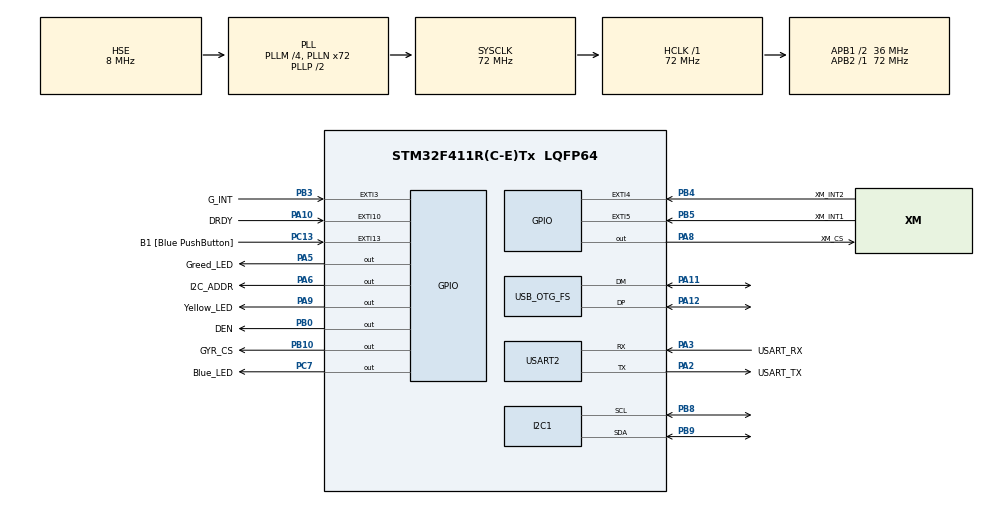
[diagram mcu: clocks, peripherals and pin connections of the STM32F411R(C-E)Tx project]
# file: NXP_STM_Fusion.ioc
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FREERTOS.INCLUDE_vTaskDelayUntil=1
FREERTOS.Tasks01=defaultTask,0,1024,StartDefaultTask
FREERTOS.configCHECK_FOR_STACK_OVERFLOW=1
FREERTOS.configUSE_MALLOC_FAILED_HOOK=1
FREERTOS.configUSE_TICK_HOOK=1
I2C1.I2C_Mode=I2C_Fast
Mcu.Family=STM32F4
Mcu.Name=STM32F411R(C-E)Tx
Mcu.Package=LQFP64
NVIC.EXTI15_10_IRQn=true\:5\:0\:false
NVIC.EXTI3_IRQn=true\:5\:0\:false
NVIC.EXTI4_IRQn=true\:5\:0\:false
NVIC.EXTI9_5_IRQn=true\:5\:0\:false
NVIC.OTG_FS_IRQn=true\:5\:0\:false
NVIC.PriorityGroup=NVIC_PRIORITYGROUP_4
NVIC.TIM1_UP_TIM10_IRQn=true\:5\:0\:false
NVIC.USART2_IRQn=true\:5\:0\:false
PA10.GPIO_Label=DRDY
PA10.Signal=GPXTI10
PA11.Mode=Device_Only
PA11.Signal=USB_OTG_FS_DM
PA12.Mode=Device_Only
PA12.Signal=USB_OTG_FS_DP
PA13.GPIO_Label=TMS
PA13.Mode=Serial-Wire
PA13.Signal=SYS_JTMS-SWDIO
PA14.GPIO_Label=TCK
PA14.Mode=Serial-Wire
PA14.Signal=SYS_JTCK-SWCLK
PA2.GPIO_Label=USART_TX
PA2.Mode=Asynchronous
PA2.Signal=USART2_TX
PA3.GPIO_Label=USART_RX
PA3.Mode=Asynchronous
PA3.Signal=USART2_RX
PA5.GPIO_Label=Greed_LED
PA5.Signal=GPIO_Output
PA6.GPIO_Label=I2C_ADDR
PA6.Signal=GPIO_Output
PA8.GPIO_Label=XM_CS
PA8.Signal=GPIO_Output
PA9.GPIO_Label=Yellow_LED
PA9.Signal=GPIO_Output
PB0.GPIO_Label=DEN
PB0.Signal=GPIO_Output
PB10.GPIO_Label=GYR_CS
PB10.Signal=GPIO_Output
PB3.GPIO_Label=G_INT
PB3.Signal=GPXTI3
PB4.GPIO_Label=XM_INT2
PB4.Signal=GPXTI4
PB5.GPIO_Label=XM_INT1
PB5.Signal=GPXTI5
PB8.Mode=I2C
PB8.Signal=I2C1_SCL
PB9.Mode=I2C
PB9.Signal=I2C1_SDA
PC13-ANTI_TAMP.GPIO_Label=B1 [Blue PushButton]
PC13-ANTI_TAMP.GPIO_ModeDefaultEXTI=GPIO_MODE_IT_RISING
PC13-ANTI_TAMP.Signal=GPXTI13
PC14-OSC32_IN.Mode=LSE-External-Oscillator
PC14-OSC32_IN.Signal=RCC_OSC32_IN
PC15-OSC32_OUT.Mode=LSE-External-Oscillator
PC15-OSC32_OUT.Signal=RCC_OSC32_OUT
PC7.GPIO_Label=Blue_LED
PC7.Signal=GPIO_Output
PH0\ -\ OSC_IN.Mode=HSE-External-Clock-Source
PH0\ -\ OSC_IN.Signal=RCC_OSC_IN
PH1\ -\ OSC_OUT.Mode=HSE-External-Clock-Source
PH1\ -\ OSC_OUT.Signal=RCC_OSC_OUT
ProjectManager.TargetToolchain=MDK-ARM V5
RCC.48MHZClocksFreq_Value=48000000
RCC.AHBFreq_Value=72000000
RCC.APB1CLKDivider=RCC_HCLK_DIV2
RCC.APB1Freq_Value=36000000
RCC.APB1TimFreq_Value=72000000
RCC.APB2Freq_Value=72000000
RCC.APB2TimFreq_Value=72000000
RCC.CortexFreq_Value=72000000
RCC.FLatency-AdvancedSettings=FLASH_LATENCY_2
RCC.HCLKFreq_Value=72000000
RCC.HSE_VALUE=8000000
RCC.HSI_VALUE=16000000
RCC.PLLM=4
RCC.PLLN=72
RCC.PLLQ=3
RCC.SYSCLKFreq_VALUE=72000000
RCC.SYSCLKSource=RCC_SYSCLKSOURCE_PLLCLK
RCC.VCOOutputFreq_Value=144000000
USB_DEVICE.PID_CDC_FS=0x5740
USB_DEVICE.USBD_HandleTypeDef=hUsbDeviceFS
USB_DEVICE.VID=0x483
USB_DEVICE.VirtualMode=Cdc
USB_DEVICE.VirtualModeFS=Cdc_FS
USB_OTG_FS.VirtualMode=Device_Only
USB_OTG_FS.vbus_sensing_enable=DISABLE
VP_CRC_VS_CRC.Mode=CRC_Activate
VP_FREERTOS_VS_ENABLE.Mode=Enabled
VP_TIM10_VS_ClockSourceINT.Mode=Enable_Timer
VP_TIM10_VS_no_output1.Mode=Output Compare1 No Output
VP_USB_DEVICE_VS_USB_DEVICE_CDC_FS.Mode=CDC_FS
board=NUCLEO-F411RE

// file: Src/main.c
/**
  ******************************************************************************
  * File Name          : main.c
  * Description        : Main program body
  ******************************************************************************
  *
  * COPYRIGHT(c) 2015 STMicroelectronics
  *
  * Redistribution and use in source and binary forms, with or without modification,
  * are permitted provided that the following conditions are met:
  *   1. Redistributions of source code must retain the above copyright notice,
  *      this list of conditions and the following disclaimer.
  *   2. Redistributions in binary form must reproduce the above copyright notice,
  *      this list of conditions and the following disclaimer in the documentation
  *      and/or other materials provided with the distribution.
  *   3. Neither the name of STMicroelectronics nor the names of its contributors
  *      may be used to endorse or promote products derived from this software
  *      without specific prior written permission.
  *
  * THIS SOFTWARE IS PROVIDED BY THE COPYRIGHT HOLDERS AND CONTRIBUTORS "AS IS"
  * AND ANY EXPRESS OR IMPLIED WARRANTIES, INCLUDING, BUT NOT LIMITED TO, THE
  * IMPLIED WARRANTIES OF MERCHANTABILITY AND FITNESS FOR A PARTICULAR PURPOSE ARE
  * DISCLAIMED. IN NO EVENT SHALL THE COPYRIGHT HOLDER OR CONTRIBUTORS BE LIABLE
  * FOR ANY DIRECT, INDIRECT, INCIDENTAL, SPECIAL, EXEMPLARY, OR CONSEQUENTIAL
  * DAMAGES (INCLUDING, BUT NOT LIMITED TO, PROCUREMENT OF SUBSTITUTE GOODS OR
  * SERVICES; LOSS OF USE, DATA, OR PROFITS; OR BUSINESS INTERRUPTION) HOWEVER
  * CAUSED AND ON ANY THEORY OF LIABILITY, WHETHER IN CONTRACT, STRICT LIABILITY,
  * OR TORT (INCLUDING NEGLIGENCE OR OTHERWISE) ARISING IN ANY WAY OUT OF THE USE
  * OF THIS SOFTWARE, EVEN IF ADVISED OF THE POSSIBILITY OF SUCH DAMAGE.
  *
  ******************************************************************************
  */
#include "stm32f4xx_hal.h"
#include "cmsis_os.h"
#include "usb_device.h"

/* USER CODE BEGIN Includes */

#include <stdio.h>

#ifdef __GNUC__
	/* With GCC/RAISONANCE, small printf (option LD Linker->Libraries->Small printf
		 set to 'Yes') calls __io_putchar() */
	#define PUTCHAR_PROTOTYPE int __io_putchar(int ch)
#else
	#define PUTCHAR_PROTOTYPE int fputc(int ch, FILE *f)
#endif /* __GNUC__ */

/* USER CODE END Includes */

CRC_HandleTypeDef hcrc;

I2C_HandleTypeDef hi2c1;

TIM_HandleTypeDef htim10;

UART_HandleTypeDef huart2;

osThreadId defaultTaskHandle;

/* USER CODE BEGIN PV */
/* Private variables ---------------------------------------------------------*/

/* USER CODE END PV */

void SystemClock_Config(void);
static void MX_GPIO_Init(void);
static void MX_CRC_Init(void);
static void MX_I2C1_Init(void);
static void MX_TIM10_Init(void);
static void MX_USART2_UART_Init(void);
void StartDefaultTask(void const * argument);

/* USER CODE BEGIN PFP */
/* Private function prototypes -----------------------------------------------*/

/* USER CODE END PFP */

/* USER CODE BEGIN 0 */

PUTCHAR_PROTOTYPE
{
  /* Place your implementation of fputc here */
  /* e.g. write a character to the EVAL_COM1 and Loop until the end of transmission */
//portENTER_CRITICAL();
	//osSemaphoreWait(serialConsoleSynchHandle, osWaitForever);

	HAL_UART_Transmit(&huart2, (uint8_t *)&ch, 1,10);
	//osSemaphoreRelease(serialConsoleSynchHandle);

//portEXIT_CRITICAL();
  return ch;
}

/* USER CODE END 0 */

int main(void)
{

  /* MCU Configuration----------------------------------------------------------*/

  /* Reset of all peripherals, Initializes the Flash interface and the Systick. */
  HAL_Init();

  /* Configure the system clock */
  SystemClock_Config();

  /* Initialize all configured peripherals */
  MX_GPIO_Init();
  MX_CRC_Init();
  MX_I2C1_Init();
  MX_TIM10_Init();
  MX_USART2_UART_Init();

  /* USER CODE BEGIN 2 */
	printf("\n\rDuvitech \302\2512015\n\r");
	printf("Sensor Fusion Demo\n\r");

  /* USER CODE END 2 */

  /* Create the thread(s) */
  /* definition and creation of defaultTask */
  osThreadDef(defaultTask, StartDefaultTask, osPriorityNormal, 0, 2048);
  defaultTaskHandle = osThreadCreate(osThread(defaultTask), NULL);

  /* Start scheduler */
  osKernelStart();

  /* We should never get here as control is now taken by the scheduler */

  /* Infinite loop */
  while (1)
  {

  }

}

/** System Clock Configuration
*/
void SystemClock_Config(void)
{

  RCC_OscInitTypeDef RCC_OscInitStruct;
  RCC_ClkInitTypeDef RCC_ClkInitStruct;

  __PWR_CLK_ENABLE();

  __HAL_PWR_VOLTAGESCALING_CONFIG(PWR_REGULATOR_VOLTAGE_SCALE1);

  RCC_OscInitStruct.OscillatorType = RCC_OSCILLATORTYPE_HSE;
  RCC_OscInitStruct.HSEState = RCC_HSE_BYPASS;
  RCC_OscInitStruct.PLL.PLLState = RCC_PLL_ON;
  RCC_OscInitStruct.PLL.PLLSource = RCC_PLLSOURCE_HSE;
  RCC_OscInitStruct.PLL.PLLM = 4;
  RCC_OscInitStruct.PLL.PLLN = 72;
  RCC_OscInitStruct.PLL.PLLP = RCC_PLLP_DIV2;
  RCC_OscInitStruct.PLL.PLLQ = 3;
  HAL_RCC_OscConfig(&RCC_OscInitStruct);

  RCC_ClkInitStruct.ClockType = RCC_CLOCKTYPE_SYSCLK|RCC_CLOCKTYPE_PCLK1;
  RCC_ClkInitStruct.SYSCLKSource = RCC_SYSCLKSOURCE_PLLCLK;
  RCC_ClkInitStruct.AHBCLKDivider = RCC_SYSCLK_DIV1;
  RCC_ClkInitStruct.APB1CLKDivider = RCC_HCLK_DIV2;
  RCC_ClkInitStruct.APB2CLKDivider = RCC_HCLK_DIV1;
  HAL_RCC_ClockConfig(&RCC_ClkInitStruct, FLASH_LATENCY_2);

  HAL_SYSTICK_Config(HAL_RCC_GetHCLKFreq()/1000);

  HAL_SYSTICK_CLKSourceConfig(SYSTICK_CLKSOURCE_HCLK);

  /* SysTick_IRQn interrupt configuration */
  HAL_NVIC_SetPriority(SysTick_IRQn, 15, 0);
}

/* CRC init function */
void MX_CRC_Init(void)
{

  hcrc.Instance = CRC;
  HAL_CRC_Init(&hcrc);

}

/* I2C1 init function */
void MX_I2C1_Init(void)
{

  hi2c1.Instance = I2C1;
  hi2c1.Init.ClockSpeed = 400000;
  hi2c1.Init.DutyCycle = I2C_DUTYCYCLE_2;
  hi2c1.Init.OwnAddress1 = 0;
  hi2c1.Init.AddressingMode = I2C_ADDRESSINGMODE_7BIT;
  hi2c1.Init.DualAddressMode = I2C_DUALADDRESS_DISABLED;
  hi2c1.Init.OwnAddress2 = 0;
  hi2c1.Init.GeneralCallMode = I2C_GENERALCALL_DISABLED;
  hi2c1.Init.NoStretchMode = I2C_NOSTRETCH_DISABLED;
  HAL_I2C_Init(&hi2c1);

}

/* TIM10 init function */
void MX_TIM10_Init(void)
{

  TIM_OC_InitTypeDef sConfigOC;

  htim10.Instance = TIM10;
  htim10.Init.Prescaler = 0;
  htim10.Init.CounterMode = TIM_COUNTERMODE_UP;
  htim10.Init.Period = 0;
  htim10.Init.ClockDivision = TIM_CLOCKDIVISION_DIV1;
  HAL_TIM_Base_Init(&htim10);

  HAL_TIM_OC_Init(&htim10);

  sConfigOC.OCMode = TIM_OCMODE_TIMING;
  sConfigOC.Pulse = 0;
  sConfigOC.OCPolarity = TIM_OCPOLARITY_HIGH;
  sConfigOC.OCFastMode = TIM_OCFAST_DISABLE;
  HAL_TIM_OC_ConfigChannel(&htim10, &sConfigOC, TIM_CHANNEL_1);

}

/* USART2 init function */
void MX_USART2_UART_Init(void)
{

  huart2.Instance = USART2;
  huart2.Init.BaudRate = 115200;
  huart2.Init.WordLength = UART_WORDLENGTH_8B;
  huart2.Init.StopBits = UART_STOPBITS_1;
  huart2.Init.Parity = UART_PARITY_NONE;
  huart2.Init.Mode = UART_MODE_TX_RX;
  huart2.Init.HwFlowCtl = UART_HWCONTROL_NONE;
  huart2.Init.OverSampling = UART_OVERSAMPLING_16;
  HAL_UART_Init(&huart2);

}

/** Configure pins as
        * Analog
        * Input
        * Output
        * EVENT_OUT
        * EXTI
*/
void MX_GPIO_Init(void)
{

  GPIO_InitTypeDef GPIO_InitStruct;

  /* GPIO Ports Clock Enable */
  __GPIOC_CLK_ENABLE();
  __GPIOH_CLK_ENABLE();
  __GPIOA_CLK_ENABLE();
  __GPIOB_CLK_ENABLE();

  /*Configure GPIO pin : B1_Pin */
  GPIO_InitStruct.Pin = B1_Pin;
  GPIO_InitStruct.Mode = GPIO_MODE_IT_RISING;
  GPIO_InitStruct.Pull = GPIO_NOPULL;
  HAL_GPIO_Init(B1_GPIO_Port, &GPIO_InitStruct);

  /*Configure GPIO pins : Greed_LED_Pin I2C_ADDR_Pin XM_CS_Pin Yellow_LED_Pin */
  GPIO_InitStruct.Pin = Greed_LED_Pin|I2C_ADDR_Pin|XM_CS_Pin|Yellow_LED_Pin;
  GPIO_InitStruct.Mode = GPIO_MODE_OUTPUT_PP;
  GPIO_InitStruct.Pull = GPIO_NOPULL;
  GPIO_InitStruct.Speed = GPIO_SPEED_LOW;
  HAL_GPIO_Init(GPIOA, &GPIO_InitStruct);

  /*Configure GPIO pins : DEN_Pin GYR_CS_Pin */
  GPIO_InitStruct.Pin = DEN_Pin|GYR_CS_Pin;
  GPIO_InitStruct.Mode = GPIO_MODE_OUTPUT_PP;
  GPIO_InitStruct.Pull = GPIO_NOPULL;
  GPIO_InitStruct.Speed = GPIO_SPEED_LOW;
  HAL_GPIO_Init(GPIOB, &GPIO_InitStruct);

  /*Configure GPIO pin : Blue_LED_Pin */
  GPIO_InitStruct.Pin = Blue_LED_Pin;
  GPIO_InitStruct.Mode = GPIO_MODE_OUTPUT_PP;
  GPIO_InitStruct.Pull = GPIO_NOPULL;
  GPIO_InitStruct.Speed = GPIO_SPEED_LOW;
  HAL_GPIO_Init(Blue_LED_GPIO_Port, &GPIO_InitStruct);

  /*Configure GPIO pin : DRDY_Pin */
  GPIO_InitStruct.Pin = DRDY_Pin;
  GPIO_InitStruct.Mode = GPIO_MODE_IT_RISING;
  GPIO_InitStruct.Pull = GPIO_NOPULL;
  HAL_GPIO_Init(DRDY_GPIO_Port, &GPIO_InitStruct);

  /*Configure GPIO pins : G_INT_Pin XM_INT2_Pin XM_INT1_Pin */
  GPIO_InitStruct.Pin = G_INT_Pin|XM_INT2_Pin|XM_INT1_Pin;
  GPIO_InitStruct.Mode = GPIO_MODE_IT_RISING;
  GPIO_InitStruct.Pull = GPIO_NOPULL;
  HAL_GPIO_Init(GPIOB, &GPIO_InitStruct);

  /* EXTI interrupt init*/
  HAL_NVIC_SetPriority(EXTI3_IRQn, 5, 0);
  HAL_NVIC_EnableIRQ(EXTI3_IRQn);

  HAL_NVIC_SetPriority(EXTI4_IRQn, 5, 0);
  HAL_NVIC_EnableIRQ(EXTI4_IRQn);

  HAL_NVIC_SetPriority(EXTI9_5_IRQn, 5, 0);
  HAL_NVIC_EnableIRQ(EXTI9_5_IRQn);

  HAL_NVIC_SetPriority(EXTI15_10_IRQn, 5, 0);
  HAL_NVIC_EnableIRQ(EXTI15_10_IRQn);

}

/* StartDefaultTask function */
void StartDefaultTask(void const * argument)
{
  /* init code for USB_DEVICE */
  MX_USB_DEVICE_Init();

  /* USER CODE BEGIN 5 */
  /* Infinite loop */
  for(;;)
  {
		HAL_GPIO_TogglePin(GPIOA, GPIO_PIN_5);
    osDelay(250);
  }
  /* USER CODE END 5 */
}

/************************ (C) COPYRIGHT STMicroelectronics *****END OF FILE****/

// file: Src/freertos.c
/**
  ******************************************************************************
  * File Name          : freertos.c
  * Description        : Code for freertos applications
  ******************************************************************************
  *
  * COPYRIGHT(c) 2015 STMicroelectronics
  *
  * Redistribution and use in source and binary forms, with or without modification,
  * are permitted provided that the following conditions are met:
  *   1. Redistributions of source code must retain the above copyright notice,
  *      this list of conditions and the following disclaimer.
  *   2. Redistributions in binary form must reproduce the above copyright notice,
  *      this list of conditions and the following disclaimer in the documentation
  *      and/or other materials provided with the distribution.
  *   3. Neither the name of STMicroelectronics nor the names of its contributors
  *      may be used to endorse or promote products derived from this software
  *      without specific prior written permission.
  *
  * THIS SOFTWARE IS PROVIDED BY THE COPYRIGHT HOLDERS AND CONTRIBUTORS "AS IS"
  * AND ANY EXPRESS OR IMPLIED WARRANTIES, INCLUDING, BUT NOT LIMITED TO, THE
  * IMPLIED WARRANTIES OF MERCHANTABILITY AND FITNESS FOR A PARTICULAR PURPOSE ARE
  * DISCLAIMED. IN NO EVENT SHALL THE COPYRIGHT HOLDER OR CONTRIBUTORS BE LIABLE
  * FOR ANY DIRECT, INDIRECT, INCIDENTAL, SPECIAL, EXEMPLARY, OR CONSEQUENTIAL
  * DAMAGES (INCLUDING, BUT NOT LIMITED TO, PROCUREMENT OF SUBSTITUTE GOODS OR
  * SERVICES; LOSS OF USE, DATA, OR PROFITS; OR BUSINESS INTERRUPTION) HOWEVER
  * CAUSED AND ON ANY THEORY OF LIABILITY, WHETHER IN CONTRACT, STRICT LIABILITY,
  * OR TORT (INCLUDING NEGLIGENCE OR OTHERWISE) ARISING IN ANY WAY OUT OF THE USE
  * OF THIS SOFTWARE, EVEN IF ADVISED OF THE POSSIBILITY OF SUCH DAMAGE.
  *
  ******************************************************************************
  */

#include "FreeRTOS.h"
#include "task.h"
#include "stm32f4xx_hal.h"

/* Hook prototypes */
void vApplicationTickHook(void);
void vApplicationStackOverflowHook(xTaskHandle xTask, signed char *pcTaskName);
void vApplicationMallocFailedHook(void);

/* USER CODE BEGIN 3 */
void vApplicationTickHook( void )
{
   /* This function will be called by each tick interrupt if
   configUSE_TICK_HOOK is set to 1 in FreeRTOSConfig.h. User code can be
   added here, but the tick hook is called from an interrupt context, so
   code must not attempt to block, and only the interrupt safe FreeRTOS API
   functions can be used (those that end in FromISR()). */
	 HAL_IncTick();
}
/* USER CODE END 3 */

/* USER CODE BEGIN 4 */
void vApplicationStackOverflowHook(xTaskHandle xTask, signed char *pcTaskName)
{
   /* Run time stack overflow checking is performed if
   configCHECK_FOR_STACK_OVERFLOW is defined to 1 or 2. This hook function is
   called if a stack overflow is detected. */
}
/* USER CODE END 4 */

/* USER CODE BEGIN 5 */
void vApplicationMallocFailedHook(void)
{
   /* vApplicationMallocFailedHook() will only be called if
   configUSE_MALLOC_FAILED_HOOK is set to 1 in FreeRTOSConfig.h. It is a hook
   function that will get called if a call to pvPortMalloc() fails.
   pvPortMalloc() is called internally by the kernel whenever a task, queue,
   timer or semaphore is created. It is also called by various parts of the
   demo application. If heap_1.c or heap_2.c are used, then the size of the
   heap available to pvPortMalloc() is defined by configTOTAL_HEAP_SIZE in
   FreeRTOSConfig.h, and the xPortGetFreeHeapSize() API function can be used
   to query the size of free heap space that remains (although it does not
   provide information on how the remaining heap might be fragmented). */
}
/* USER CODE END 5 */

/************************ (C) COPYRIGHT STMicroelectronics *****END OF FILE****/
